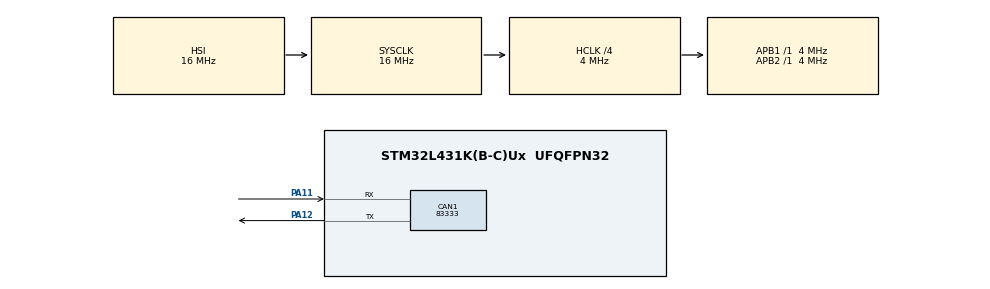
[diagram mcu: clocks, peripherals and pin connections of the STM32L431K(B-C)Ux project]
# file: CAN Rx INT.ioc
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CAN1.CalculateBaudRate=83333
CAN1.CalculateTimeBit=12000.00
CAN1.CalculateTimeQuantum=4000.0
Mcu.Family=STM32L4
Mcu.Name=STM32L431K(B-C)Ux
Mcu.Package=UFQFPN32
NVIC.CAN1_RX0_IRQn=true\:0\:0\:false\:false\:true\:true\:true
NVIC.CAN1_TX_IRQn=true\:0\:0\:false\:false\:true\:true\:true
NVIC.PriorityGroup=NVIC_PRIORITYGROUP_4
PA11.Mode=CAN_Activate
PA11.Signal=CAN1_RX
PA12.Mode=CAN_Activate
PA12.Signal=CAN1_TX
ProjectManager.HeapSize=0x200
ProjectManager.StackSize=0x400
ProjectManager.TargetToolchain=STM32CubeIDE
RCC.AHBCLKDivider=RCC_SYSCLK_DIV4
RCC.AHBFreq_Value=4000000
RCC.APB1Freq_Value=4000000
RCC.APB1TimFreq_Value=4000000
RCC.APB2Freq_Value=4000000
RCC.APB2TimFreq_Value=4000000
RCC.CortexFreq_Value=4000000
RCC.HCLKFreq_Value=4000000
RCC.HSE_VALUE=8000000
RCC.HSI48_VALUE=48000000
RCC.HSI_VALUE=16000000
RCC.LSE_VALUE=32768
RCC.MSI_VALUE=4000000
RCC.SYSCLKFreq_VALUE=16000000
RCC.SYSCLKSource=RCC_SYSCLKSOURCE_HSI
RCC.VCOOutputFreq_Value=32000000
board=custom

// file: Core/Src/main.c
/* USER CODE BEGIN Header */
/**
 ******************************************************************************
 * @file           : main.c
 * @brief          : Main program body
 ******************************************************************************
 * @attention
 *
 * <h2><center>&copy; Copyright (c) 2024 STMicroelectronics.
 * All rights reserved.</center></h2>
 *
 * This software component is licensed by ST under BSD 3-Clause license,
 * the "License"; You may not use this file except in compliance with the
 * License. You may obtain a copy of the License at:
 *                        opensource.org/licenses/BSD-3-Clause
 *
 ******************************************************************************
 */
/* USER CODE END Header */
#include "main.h"

CAN_HandleTypeDef hcan1;

/* USER CODE BEGIN PV */

CAN_HandleTypeDef hcan1;
CAN_TxHeaderTypeDef pHeader; //declare a specific header for message transmittions
CAN_RxHeaderTypeDef pRxHeader; //declare header for message reception
uint32_t TxMailbox;
uint8_t a,r; //declare byte to be transmitted //declare a receive byte
CAN_FilterTypeDef sFilterConfig; //declare CAN filter structure

/* USER CODE END PV */

void SystemClock_Config(void);
static void MX_GPIO_Init(void);
static void MX_CAN1_Init(void);

int main(void)
{
  /* USER CODE BEGIN 1 */

	CoreDebug->DEMCR |= CoreDebug_DEMCR_TRCENA_Msk;
	// Enable ITM
	ITM->TCR = ITM_TCR_ITMENA_Msk;
	// Enable stimulus port 0
	ITM->TER = 0x1;

  /* USER CODE END 1 */

  /* MCU Configuration--------------------------------------------------------*/

  /* Reset of all peripherals, Initializes the Flash interface and the Systick. */
  HAL_Init();

  /* Configure the system clock */
  SystemClock_Config();

  /* Initialize all configured peripherals */
  MX_GPIO_Init();
  MX_CAN1_Init();
  /* USER CODE BEGIN 2 */

	HAL_GPIO_WritePin(GPIOA, GPIO_PIN_8, GPIO_PIN_RESET);

	pHeader.DLC=1; //give message size of 1 byte
	pHeader.IDE=CAN_ID_STD; //set identifier to standard
	pHeader.RTR=CAN_RTR_DATA; //set data type to remote transmission request?
	pHeader.StdId=0x244; //define a standard identifier, used for message identification by filters

	//filter one (stack light blink)
	sFilterConfig.FilterFIFOAssignment=CAN_FILTER_FIFO0; //set fifo assignment
	sFilterConfig.FilterIdHigh=0x245<<5; //11 bit id and can id is in bit 16-32 so we need to shift it for 5
	sFilterConfig.FilterIdLow=0;
	sFilterConfig.FilterMaskIdHigh=0;
	sFilterConfig.FilterMaskIdLow=0;
	sFilterConfig.FilterScale=CAN_FILTERSCALE_32BIT; //set filter scale
	sFilterConfig.FilterActivation=ENABLE;

	HAL_CAN_ConfigFilter(&hcan1, &sFilterConfig); //configure CAN filter

	HAL_CAN_Start(&hcan1); //start CAN
	HAL_CAN_ActivateNotification(&hcan1, CAN_IT_RX_FIFO0_MSG_PENDING); //enable interrupts

  /* USER CODE END 2 */

  /* Infinite loop */
	while (1)
	{

	}
}

void SystemClock_Config(void)
{
  RCC_OscInitTypeDef RCC_OscInitStruct = {0};
  RCC_ClkInitTypeDef RCC_ClkInitStruct = {0};

  /** Configure the main internal regulator output voltage
  */
  if (HAL_PWREx_ControlVoltageScaling(PWR_REGULATOR_VOLTAGE_SCALE1) != HAL_OK)
  {
    Error_Handler();
  }
  /** Initializes the RCC Oscillators according to the specified parameters
  * in the RCC_OscInitTypeDef structure.
  */
  RCC_OscInitStruct.OscillatorType = RCC_OSCILLATORTYPE_HSI;
  RCC_OscInitStruct.HSIState = RCC_HSI_ON;
  RCC_OscInitStruct.HSICalibrationValue = RCC_HSICALIBRATION_DEFAULT;
  RCC_OscInitStruct.PLL.PLLState = RCC_PLL_NONE;
  if (HAL_RCC_OscConfig(&RCC_OscInitStruct) != HAL_OK)
  {
    Error_Handler();
  }
  /** Initializes the CPU, AHB and APB buses clocks
  */
  RCC_ClkInitStruct.ClockType = RCC_CLOCKTYPE_HCLK|RCC_CLOCKTYPE_SYSCLK
                              |RCC_CLOCKTYPE_PCLK1|RCC_CLOCKTYPE_PCLK2;
  RCC_ClkInitStruct.SYSCLKSource = RCC_SYSCLKSOURCE_HSI;
  RCC_ClkInitStruct.AHBCLKDivider = RCC_SYSCLK_DIV4;
  RCC_ClkInitStruct.APB1CLKDivider = RCC_HCLK_DIV1;
  RCC_ClkInitStruct.APB2CLKDivider = RCC_HCLK_DIV1;

  if (HAL_RCC_ClockConfig(&RCC_ClkInitStruct, FLASH_LATENCY_0) != HAL_OK)
  {
    Error_Handler();
  }
}

static void MX_CAN1_Init(void)
{

  hcan1.Instance = CAN1;
  hcan1.Init.Prescaler = 1;
  hcan1.Init.Mode = CAN_MODE_NORMAL;
  hcan1.Init.SyncJumpWidth = CAN_SJW_1TQ;
  hcan1.Init.TimeSeg1 = CAN_BS1_6TQ;
  hcan1.Init.TimeSeg2 = CAN_BS2_1TQ;
  hcan1.Init.TimeTriggeredMode = DISABLE;
  hcan1.Init.AutoBusOff = DISABLE;
  hcan1.Init.AutoWakeUp = DISABLE;
  hcan1.Init.AutoRetransmission = DISABLE;
  hcan1.Init.ReceiveFifoLocked = DISABLE;
  hcan1.Init.TransmitFifoPriority = DISABLE;
  if (HAL_CAN_Init(&hcan1) != HAL_OK)
  {
    Error_Handler();
  }

}

static void MX_GPIO_Init(void)
{

  /* GPIO Ports Clock Enable */
  __HAL_RCC_GPIOA_CLK_ENABLE();

}

void Error_Handler(void)
{
	__disable_irq();
	while (1)
	{
	}
}

/************************ (C) COPYRIGHT STMicroelectronics *****END OF FILE****/
